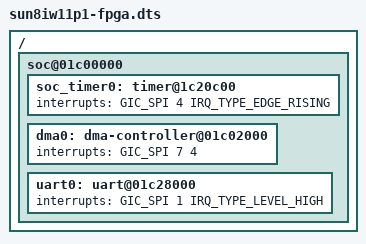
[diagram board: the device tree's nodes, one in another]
/*
 * Allwinner Technology CO., Ltd. sun8iw11p1 fpga board.
 *
 * fpga board support.
 */

/dts-v1/;
#include "sun8iw11p1.dtsi"

/{

	soc@01c00000 {
		soc_timer0: timer@1c20c00 {
			interrupts = <GIC_SPI 4 IRQ_TYPE_EDGE_RISING>;
		};

		dma0:dma-controller@01c02000 {
			interrupts = <GIC_SPI 7 4>;
		};

		uart0: uart@01c28000 {
			interrupts = <GIC_SPI 1 IRQ_TYPE_LEVEL_HIGH>;           /* uart0 is IRQ33 on fpga */
			status = "okay";
		};


	};
};
